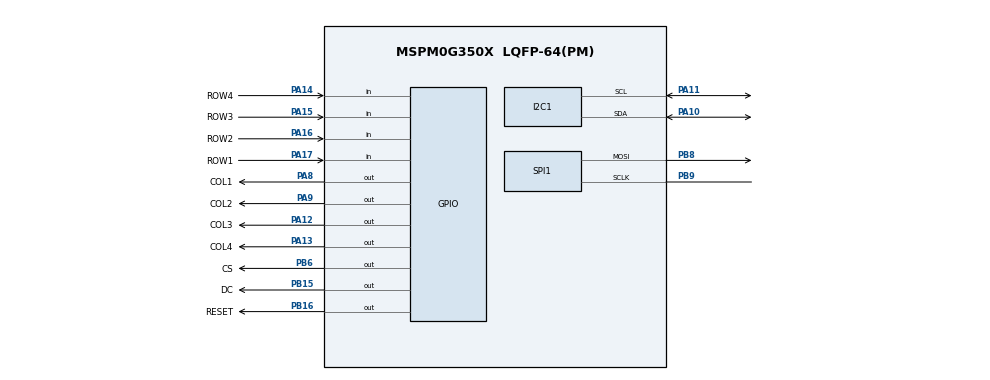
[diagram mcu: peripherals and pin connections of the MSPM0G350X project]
/**
 * @cliArgs --device "MSPM0G350X" --part "Default" --package "LQFP-64(PM)" --product "mspm0_sdk@2.11.00.07"
 * @versions {"tool":"1.26.2+4477"}
 */

/**
 * Import the modules used in this configuration.
 */
const GPIO   = scripting.addModule("/ti/driverlib/GPIO", {}, false);
const GPIO1  = GPIO.addInstance();
const GPIO2  = GPIO.addInstance();
const GPIO3  = GPIO.addInstance();
const I2C    = scripting.addModule("/ti/driverlib/I2C", {}, false);
const I2C1   = I2C.addInstance();
const SPI    = scripting.addModule("/ti/driverlib/SPI", {}, false);
const SPI1   = SPI.addInstance();
const SYSCTL = scripting.addModule("/ti/driverlib/SYSCTL");

/**
 * Write custom configuration values to the imported modules.
 */
GPIO1.$name                          = "LCD_CTRL";
GPIO1.port                           = "PORTB";
GPIO1.associatedPins.create(3);
GPIO1.associatedPins[0].$name        = "CS";
GPIO1.associatedPins[0].initialValue = "SET";
GPIO1.associatedPins[0].pin.$assign  = "PB6";
GPIO1.associatedPins[1].$name        = "DC";
GPIO1.associatedPins[1].initialValue = "SET";
GPIO1.associatedPins[1].pin.$assign  = "PB15";
GPIO1.associatedPins[2].$name        = "RESET";
GPIO1.associatedPins[2].initialValue = "SET";
GPIO1.associatedPins[2].pin.$assign  = "PB16";

const Board = scripting.addModule("/ti/driverlib/Board", {}, false);

GPIO2.$name                          = "KEYPAD_COLS";
GPIO2.port                           = "PORTA";
GPIO2.associatedPins.create(4);
GPIO2.associatedPins[0].$name        = "COL1";
GPIO2.associatedPins[0].initialValue = "SET";
GPIO2.associatedPins[0].pin.$assign  = "PA8";
GPIO2.associatedPins[1].$name        = "COL2";
GPIO2.associatedPins[1].initialValue = "SET";
GPIO2.associatedPins[1].pin.$assign  = "PA9";
GPIO2.associatedPins[2].$name        = "COL3";
GPIO2.associatedPins[2].initialValue = "SET";
GPIO2.associatedPins[2].pin.$assign  = "PA12";
GPIO2.associatedPins[3].$name        = "COL4";
GPIO2.associatedPins[3].initialValue = "SET";
GPIO2.associatedPins[3].pin.$assign  = "PA13";

GPIO3.$name                              = "KEYPAD_ROWS";
GPIO3.port                               = "PORTA";
GPIO3.associatedPins.create(4);
GPIO3.associatedPins[0].$name            = "ROW1";
GPIO3.associatedPins[0].direction        = "INPUT";
GPIO3.associatedPins[0].internalResistor = "PULL_UP";
GPIO3.associatedPins[0].pin.$assign      = "PA17";
GPIO3.associatedPins[1].$name            = "ROW2";
GPIO3.associatedPins[1].direction        = "INPUT";
GPIO3.associatedPins[1].internalResistor = "PULL_UP";
GPIO3.associatedPins[1].pin.$assign      = "PA16";
GPIO3.associatedPins[2].$name            = "ROW3";
GPIO3.associatedPins[2].direction        = "INPUT";
GPIO3.associatedPins[2].internalResistor = "PULL_UP";
GPIO3.associatedPins[2].pin.$assign      = "PA15";
GPIO3.associatedPins[3].$name            = "ROW4";
GPIO3.associatedPins[3].direction        = "INPUT";
GPIO3.associatedPins[3].internalResistor = "PULL_UP";
GPIO3.associatedPins[3].pin.$assign      = "PA14";

I2C1.$name                         = "I2C_0";
I2C1.peripheral.sdaPin.$assign     = "PA10";
I2C1.peripheral.sclPin.$assign     = "PA11";
I2C1.sdaPinConfig.$name            = "ti_driverlib_gpio_GPIOPinGeneric2";
I2C1.sdaPinConfig.enableConfig     = true;
I2C1.sdaPinConfig.internalResistor = "PULL_UP";
I2C1.sclPinConfig.$name            = "ti_driverlib_gpio_GPIOPinGeneric3";
I2C1.sclPinConfig.enableConfig     = true;
I2C1.sclPinConfig.internalResistor = "PULL_UP";

SPI1.$name                              = "SPI_LCD";
SPI1.frameFormat                        = "MOTO3";
SPI1.direction                          = "PICO";
SPI1.targetBitRate                      = 4000000;
SPI1.chipSelect                         = [];
SPI1.sclkPinConfig.$name                = "ti_driverlib_gpio_GPIOPinGeneric0";
SPI1.sclkPinConfig.direction            = scripting.forceWrite("OUTPUT");
SPI1.sclkPinConfig.onlyInternalResistor = scripting.forceWrite(false);
SPI1.sclkPinConfig.passedPeripheralType = scripting.forceWrite("Digital");
SPI1.mosiPinConfig.$name                = "ti_driverlib_gpio_GPIOPinGeneric1";
SPI1.mosiPinConfig.direction            = scripting.forceWrite("OUTPUT");
SPI1.mosiPinConfig.hideOutputInversion  = scripting.forceWrite(false);
SPI1.mosiPinConfig.onlyInternalResistor = scripting.forceWrite(false);
SPI1.mosiPinConfig.passedPeripheralType = scripting.forceWrite("Digital");
SPI1.peripheral.$assign                 = "SPI1";
SPI1.peripheral.sclkPin.$assign         = "PB9";
SPI1.peripheral.mosiPin.$assign         = "PB8";

SYSCTL.forceDefaultClkConfig = true;
SYSCTL.clockTreeEn           = true;

/**
 * Pinmux solution for unlocked pins/peripherals. This ensures that minor changes to the automatic solver in a future
 * version of the tool will not impact the pinmux you originally saw.  These lines can be completely deleted in order to
 * re-solve from scratch.
 */
Board.peripheral.$suggestSolution          = "DEBUGSS";
Board.peripheral.swclkPin.$suggestSolution = "PA20";
Board.peripheral.swdioPin.$suggestSolution = "PA19";
I2C1.peripheral.$suggestSolution           = "I2C0";
